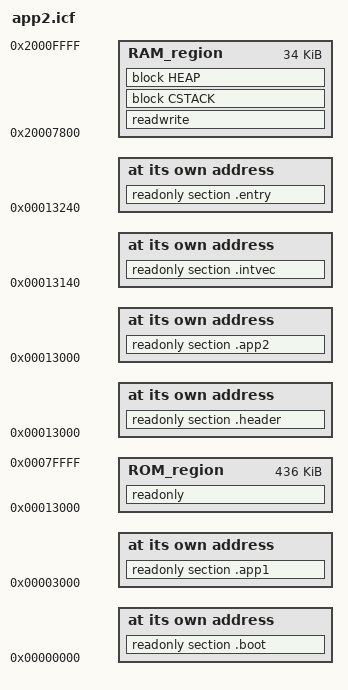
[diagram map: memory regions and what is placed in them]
/*###ICF### Section handled by ICF editor, don't touch! ****/
/*-Editor annotation file-*/
/* IcfEditorFile="$TOOLKIT_DIR$\config\ide\IcfEditor\cortex_v1_0.xml" */
/*-Specials-*/
define exported symbol __ICFEDIT_BOOT_start__   = 0x00000000;                       //Boot分配8K
define exported symbol __ICFEDIT_BOOT_intvec__  = __ICFEDIT_BOOT_start__ ;          //
define exported symbol __ICFEDIT_BOOT_entry__   = __ICFEDIT_BOOT_start__ + 0x200;   //API接口

define exported symbol __ICFEDIT_APP1_start__   = __ICFEDIT_BOOT_start__ + 0x3000;  //APP1分配64K
define exported symbol __ICFEDIT_APP1_intvec__  = __ICFEDIT_APP1_start__ + 0x140;    //
define exported symbol __ICFEDIT_APP1_entry__   = __ICFEDIT_APP1_start__ + 0x340;   //API接口

define exported symbol __ICFEDIT_APP2_start__   = __ICFEDIT_BOOT_start__ + 0x13000; //APP2分配剩下的512-78K
define exported symbol __ICFEDIT_APP2_intvec__  = __ICFEDIT_APP2_start__ + 0x140;    //
define exported symbol __ICFEDIT_APP2_entry__   = __ICFEDIT_APP2_start__ + 0x240;   //API接口

define symbol __ICFEDIT_intvec_start__ = __ICFEDIT_APP2_intvec__;

/*-Memory Regions-*/
define symbol __ICFEDIT_region_ROM_start__ = __ICFEDIT_APP2_start__;
define symbol __ICFEDIT_region_ROM_end__   = 0x0007FFFF;//共512K FLASH 
define symbol __ICFEDIT_region_RAM_start__ = 0x20007800;//36K RAM
define symbol __ICFEDIT_region_RAM_end__   = 0x2000FFFF;//共64K RAM
/*-Sizes-*/
if (!isdefinedsymbol(__ICFEDIT_size_cstack__)) {
define symbol __ICFEDIT_size_cstack__ = 0x0;
}
if (!isdefinedsymbol(__ICFEDIT_size_heap__)) {
define symbol __ICFEDIT_size_heap__ = 0x0;
}
/**** End of ICF editor section. ###ICF###*/

define memory mem with size = 4G;
define region ROM_region   = mem:[from __ICFEDIT_region_ROM_start__   to __ICFEDIT_region_ROM_end__];
define region RAM_region   = mem:[from __ICFEDIT_region_RAM_start__   to __ICFEDIT_region_RAM_end__];

define block CSTACK    with alignment = 8, size = __ICFEDIT_size_cstack__   { };
define block HEAP      with alignment = 8, size = __ICFEDIT_size_heap__     { };

initialize by copy { readwrite };
do not initialize  { section .noinit };

place at address mem:__ICFEDIT_APP2_start__     { readonly section .header };
place at address mem:__ICFEDIT_intvec_start__   { readonly section .intvec };
place at address mem:__ICFEDIT_APP2_entry__     { readonly section .entry };
place at address mem:__ICFEDIT_BOOT_start__     { readonly section .boot };
place at address mem:__ICFEDIT_APP1_start__     { readonly section .app1 };
place at address mem:__ICFEDIT_APP2_start__     { readonly section .app2 };

place in ROM_region   { readonly };
place in RAM_region   { readwrite, block CSTACK, block HEAP };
